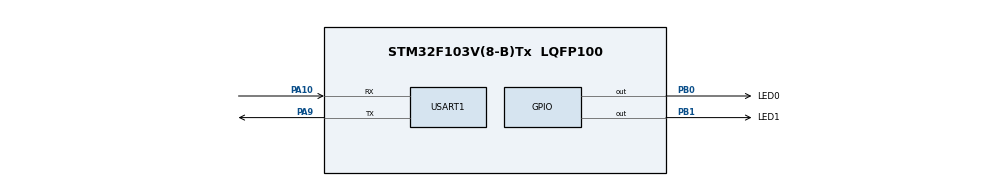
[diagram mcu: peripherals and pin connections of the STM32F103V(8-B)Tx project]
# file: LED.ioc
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Mcu.Family=STM32F1
Mcu.Name=STM32F103V(8-B)Tx
Mcu.Package=LQFP100
NVIC.PriorityGroup=NVIC_PRIORITYGROUP_4
OSC_IN.Mode=HSE-External-Oscillator
OSC_IN.Signal=RCC_OSC_IN
OSC_OUT.Mode=HSE-External-Oscillator
OSC_OUT.Signal=RCC_OSC_OUT
PA10.Mode=Asynchronous
PA10.Signal=USART1_RX
PA13.Mode=Serial_Wire
PA13.Signal=SYS_JTMS-SWDIO
PA14.Mode=Serial_Wire
PA14.Signal=SYS_JTCK-SWCLK
PA9.Mode=Asynchronous
PA9.Signal=USART1_TX
PB0.GPIO_Label=LED0
PB0.GPIO_ModeDefaultOutputPP=GPIO_MODE_OUTPUT_PP
PB0.GPIO_PuPd=GPIO_PULLUP
PB0.GPIO_Speed=GPIO_SPEED_FREQ_HIGH
PB0.PinState=GPIO_PIN_SET
PB0.Signal=GPIO_Output
PB1.GPIO_Label=LED1
PB1.GPIO_PuPd=GPIO_PULLUP
PB1.GPIO_Speed=GPIO_SPEED_FREQ_HIGH
PB1.PinState=GPIO_PIN_SET
PB1.Signal=GPIO_Output
ProjectManager.HeapSize=0x200
ProjectManager.StackSize=0x400
ProjectManager.TargetToolchain=STM32CubeIDE
RCC.APB1Freq_Value=8000000
RCC.APB2Freq_Value=8000000
USART1.Parity=PARITY_EVEN
USART1.VirtualMode=VM_ASYNC
board=custom

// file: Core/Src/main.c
/* USER CODE BEGIN Header */
/**
  ******************************************************************************
  * @file           : main.c
  * @brief          : Main program body
  ******************************************************************************
  * @attention
  *
  * Copyright (c) 2021 STMicroelectronics.
  * All rights reserved.
  *
  * This software is licensed under terms that can be found in the LICENSE file
  * in the root directory of this software component.
  * If no LICENSE file comes with this software, it is provided AS-IS.
  *
  ******************************************************************************
  */
/* USER CODE END Header */
#include "main.h"

UART_HandleTypeDef huart1;

void SystemClock_Config(void);
static void MX_GPIO_Init(void);
static void MX_USART1_UART_Init(void);

int main(void)
{
  /* USER CODE BEGIN 1 */
    unsigned char Sendbuf[]="rymcu.com nebula-Pi32";
  /* USER CODE END 1 */

  /* MCU Configuration--------------------------------------------------------*/

  /* Reset of all peripherals, Initializes the Flash interface and the Systick. */
  HAL_Init();

  /* Configure the system clock */
  SystemClock_Config();

  /* Initialize all configured peripherals */
  MX_GPIO_Init();
  MX_USART1_UART_Init();
  /* USER CODE BEGIN 2 */
    HAL_GPIO_WritePin(LED0_GPIO_Port,LED0_Pin,GPIO_PIN_SET);
    HAL_GPIO_WritePin(LED1_GPIO_Port,LED1_Pin,GPIO_PIN_RESET);

  /* USER CODE END 2 */

    HAL_UART_Transmit(&huart1,&Sendbuf,10,1);
  /* Infinite loop */
  while (1)
  {
      HAL_GPIO_TogglePin(LED1_GPIO_Port,LED1_Pin);
      HAL_Delay(500);
  }
}

void SystemClock_Config(void)
{
  RCC_OscInitTypeDef RCC_OscInitStruct = {0};
  RCC_ClkInitTypeDef RCC_ClkInitStruct = {0};

  /** Initializes the RCC Oscillators according to the specified parameters
  * in the RCC_OscInitTypeDef structure.
  */
  RCC_OscInitStruct.OscillatorType = RCC_OSCILLATORTYPE_HSI;
  RCC_OscInitStruct.HSIState = RCC_HSI_ON;
  RCC_OscInitStruct.HSICalibrationValue = RCC_HSICALIBRATION_DEFAULT;
  RCC_OscInitStruct.PLL.PLLState = RCC_PLL_NONE;
  if (HAL_RCC_OscConfig(&RCC_OscInitStruct) != HAL_OK)
  {
    Error_Handler();
  }
  /** Initializes the CPU, AHB and APB buses clocks
  */
  RCC_ClkInitStruct.ClockType = RCC_CLOCKTYPE_HCLK|RCC_CLOCKTYPE_SYSCLK
                              |RCC_CLOCKTYPE_PCLK1|RCC_CLOCKTYPE_PCLK2;
  RCC_ClkInitStruct.SYSCLKSource = RCC_SYSCLKSOURCE_HSI;
  RCC_ClkInitStruct.AHBCLKDivider = RCC_SYSCLK_DIV1;
  RCC_ClkInitStruct.APB1CLKDivider = RCC_HCLK_DIV1;
  RCC_ClkInitStruct.APB2CLKDivider = RCC_HCLK_DIV1;

  if (HAL_RCC_ClockConfig(&RCC_ClkInitStruct, FLASH_LATENCY_0) != HAL_OK)
  {
    Error_Handler();
  }
}

static void MX_USART1_UART_Init(void)
{

  huart1.Instance = USART1;
  huart1.Init.BaudRate = 115200;
  huart1.Init.WordLength = UART_WORDLENGTH_9B;
  huart1.Init.StopBits = UART_STOPBITS_1;
  huart1.Init.Parity = UART_PARITY_EVEN;
  huart1.Init.Mode = UART_MODE_TX_RX;
  huart1.Init.HwFlowCtl = UART_HWCONTROL_NONE;
  huart1.Init.OverSampling = UART_OVERSAMPLING_16;
  if (HAL_UART_Init(&huart1) != HAL_OK)
  {
    Error_Handler();
  }

}

static void MX_GPIO_Init(void)
{
  GPIO_InitTypeDef GPIO_InitStruct = {0};

  /* GPIO Ports Clock Enable */
  __HAL_RCC_GPIOB_CLK_ENABLE();
  __HAL_RCC_GPIOA_CLK_ENABLE();

  /*Configure GPIO pin Output Level */
  HAL_GPIO_WritePin(GPIOB, GPIO_PIN_0|GPIO_PIN_1, GPIO_PIN_SET);

  /*Configure GPIO pins : PB0 PB1 */
  GPIO_InitStruct.Pin = GPIO_PIN_0|GPIO_PIN_1;
  GPIO_InitStruct.Mode = GPIO_MODE_OUTPUT_PP;
  GPIO_InitStruct.Pull = GPIO_PULLUP;
  GPIO_InitStruct.Speed = GPIO_SPEED_FREQ_HIGH;
  HAL_GPIO_Init(GPIOB, &GPIO_InitStruct);

}

void Error_Handler(void)
{
  __disable_irq();
  while (1)
  {
  }
}
